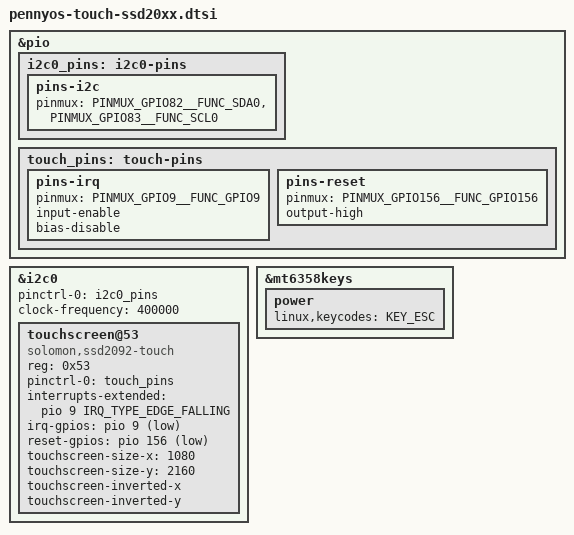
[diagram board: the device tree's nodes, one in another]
// SPDX-License-Identifier: (GPL-2.0-only OR MIT)
/*
 * Main-panel touch on SSD2092 units: the touch half of the Solomon TDDI chip, at
 * 0x53 on i2c0. (Units with the NT36672 panel have a Novatek controller at 0x62
 * on the same bus instead.) Pins from the vendor dtbo: INT = GPIO9 (EINT9,
 * falling), RST = GPIO156, I2C0 = GPIO82 (SDA) / GPIO83 (SCL).
 */
&pio {
	i2c0_pins: i2c0-pins {
		pins-i2c {
			pinmux = <PINMUX_GPIO82__FUNC_SDA0>,
				 <PINMUX_GPIO83__FUNC_SCL0>;
		};
	};

	touch_pins: touch-pins {
		pins-irq {
			pinmux = <PINMUX_GPIO9__FUNC_GPIO9>;
			input-enable;
			bias-disable;
		};
		pins-reset {
			pinmux = <PINMUX_GPIO156__FUNC_GPIO156>;
			output-high;
		};
	};
};

&i2c0 {
	#address-cells = <1>;
	#size-cells = <0>;
	pinctrl-names = "default";
	pinctrl-0 = <&i2c0_pins>;
	clock-frequency = <400000>;
	status = "okay";

	touchscreen@53 {
		compatible = "solomon,ssd2092-touch";
		reg = <0x53>;
		pinctrl-names = "default";
		pinctrl-0 = <&touch_pins>;
		interrupts-extended = <&pio 9 IRQ_TYPE_EDGE_FALLING>;
		irq-gpios = <&pio 9 GPIO_ACTIVE_LOW>;
		reset-gpios = <&pio 156 GPIO_ACTIVE_LOW>;
		touchscreen-size-x = <1080>;
		touchscreen-size-y = <2160>;
		/*
		 * Raw coordinates are rotated 180 degrees relative to the panel's
		 * scan-out (measured: landscape top-left reads x~865 y~175).
		 */
		touchscreen-inverted-x;
		touchscreen-inverted-y;
	};
};

/*
 * The Esc/On key is the PMIC power key. Report it as Esc so that it is usable as
 * a key; forced power-off stays available through the PMIC long-press reset
 * (pennyos-power-key.dtsi).
 */
&mt6358keys {
	power {
		linux,keycodes = <KEY_ESC>;
	};
};
